# N32H7xx register map
Vendor: Nationstech Ltd.; File version: 1.0
CPU: CM7 r1p1, little endian, MPU, FPU, 4 interrupt priority bits
Registers are 32-bit, read-write, reset 0x0 unless marked. A register's access mark holds for its fields unless they carry their own. Offsets are from the block's base; [hi:lo] are bit positions; {n}, {i} and the like mark numbered series; 'fields as' and 'values as' point back to an identical list.

## ETH1 — Ethernet 1
Base 0x400F4000
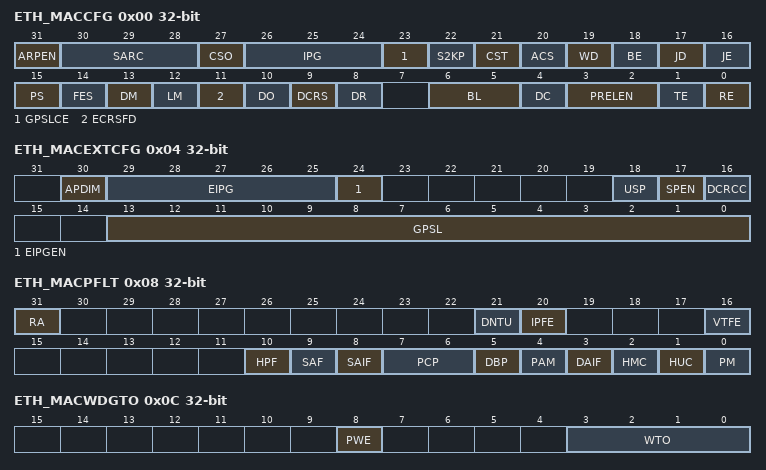
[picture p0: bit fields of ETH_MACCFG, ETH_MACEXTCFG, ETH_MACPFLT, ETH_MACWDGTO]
0x00 ETH_MACCFG
  [31] ARPEN, [30:28] SARC, [27] CSO, [26:24] IPG, [23] GPSLCE, [22] S2KP, [21] CST, [20] ACS, [19] WD, [18] BE, [17] JD, [16] JE, [15] PS, [14] FES, [13] DM, [12] LM, [11] ECRSFD, [10] DO, [9] DCRS, [8] DR, [6:5] BL, [4] DC, [3:2] PRELEN, [1] TE, [0] RE
0x04 ETH_MACEXTCFG
  [30] APDIM, [29:25] EIPG, [24] EIPGEN, [18] USP, [17] SPEN, [16] DCRCC, [13:0] GPSL
0x08 ETH_MACPFLT
  [31] RA, [21] DNTU, [20] IPFE, [16] VTFE, [10] HPF, [9] SAF, [8] SAIF, [7:6] PCP, [5] DBP, [4] PAM, [3] DAIF, [2] HMC, [1] HUC, [0] PM
0x0C ETH_MACWDGTO
  [8] PWE, [3:0] WTO
0x10 ETH_MACHASHTR0
  [31:0] HT31T0
0x14 ETH_MACHASHTR1
  [31:0] HT63T32
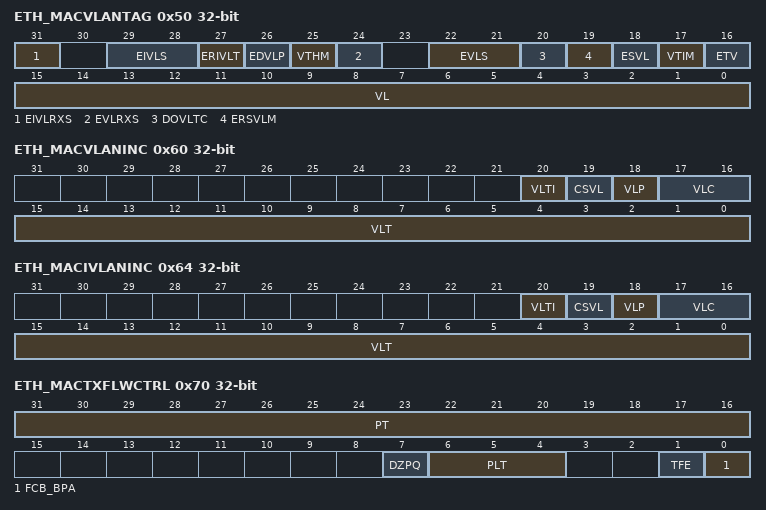
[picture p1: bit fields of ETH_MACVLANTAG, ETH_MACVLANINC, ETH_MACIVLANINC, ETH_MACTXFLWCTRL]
0x50 ETH_MACVLANTAG
  [31] EIVLRXS, [29:28] EIVLS, [27] ERIVLT, [26] EDVLP, [25] VTHM, [24] EVLRXS, [22:21] EVLS, [20] DOVLTC, [19] ERSVLM, [18] ESVL, [17] VTIM, [16] ETV, [15:0] VL
0x58 ETH_MACVHASHT
  [15:0] VLHT
0x60 ETH_MACVLANINC
  [20] VLTI, [19] CSVL, [18] VLP, [17:16] VLC, [15:0] VLT
0x64 ETH_MACIVLANINC
  [20] VLTI, [19] CSVL, [18] VLP, [17:16] VLC, [15:0] VLT
0x70 ETH_MACTXFLWCTRL
  [31:16] PT, [7] DZPQ, [6:4] PLT, [1] TFE, [0] FCB_BPA
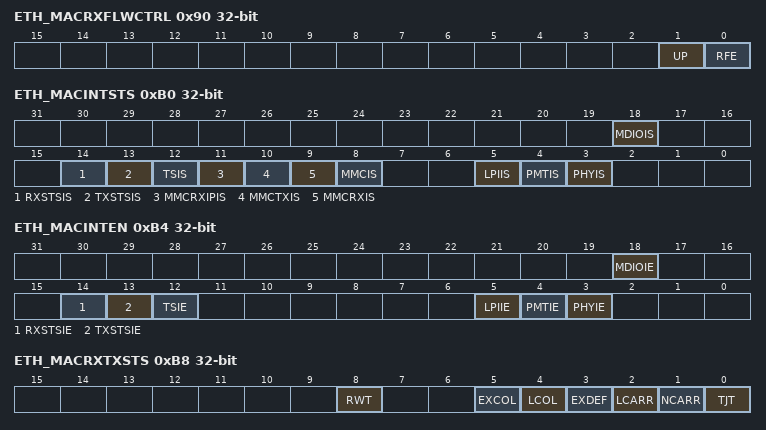
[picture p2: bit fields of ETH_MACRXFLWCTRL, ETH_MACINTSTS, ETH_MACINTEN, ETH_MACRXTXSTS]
0x90 ETH_MACRXFLWCTRL
  [1] UP, [0] RFE
0xB0 ETH_MACINTSTS ro
  [18] MDIOIS, [14] RXSTSIS, [13] TXSTSIS, [12] TSIS, [11] MMCRXIPIS, [10] MMCTXIS, [9] MMCRXIS, [8] MMCIS, [5] LPIIS, [4] PMTIS, [3] PHYIS
0xB4 ETH_MACINTEN
  [18] MDIOIE, [14] RXSTSIE, [13] TXSTSIE, [12] TSIE, [5] LPIIE, [4] PMTIE, [3] PHYIE
0xB8 ETH_MACRXTXSTS ro
  [8] RWT, [5] EXCOL, [4] LCOL, [3] EXDEF, [2] LCARR, [1] NCARR, [0] TJT
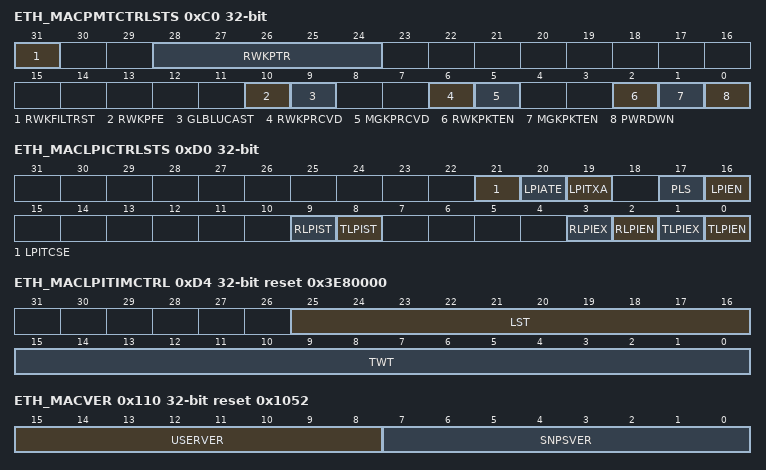
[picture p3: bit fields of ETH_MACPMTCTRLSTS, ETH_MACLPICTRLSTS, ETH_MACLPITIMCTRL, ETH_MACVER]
0xC0 ETH_MACPMTCTRLSTS
  [31] RWKFILTRST, [28:24] RWKPTR ro, [10] RWKPFE, [9] GLBLUCAST, [6] RWKPRCVD ro, [5] MGKPRCVD ro, [2] RWKPKTEN, [1] MGKPKTEN, [0] PWRDWN
0xC4 ETH_MACRWUPFLT
  [31:0] WKUPFRMFTR
0xD0 ETH_MACLPICTRLSTS
  [21] LPITCSE, [20] LPIATE, [19] LPITXA, [17] PLS, [16] LPIEN, [9] RLPIST ro, [8] TLPIST ro, [3] RLPIEX ro, [2] RLPIEN ro, [1] TLPIEX ro, [0] TLPIEN ro
0xD4 ETH_MACLPITIMCTRL reset 0x3E80000
  [25:16] LST, [15:0] TWT
0xD8 ETH_MACLPIETYTIM
  [19:3] LPIET
0xDC ETH_MAC1USTICCNT reset 0x63
  [11:0] TIC1USCNTR
0x110 ETH_MACVER ro reset 0x1052
  [15:8] USERVER, [7:0] SNPSVER
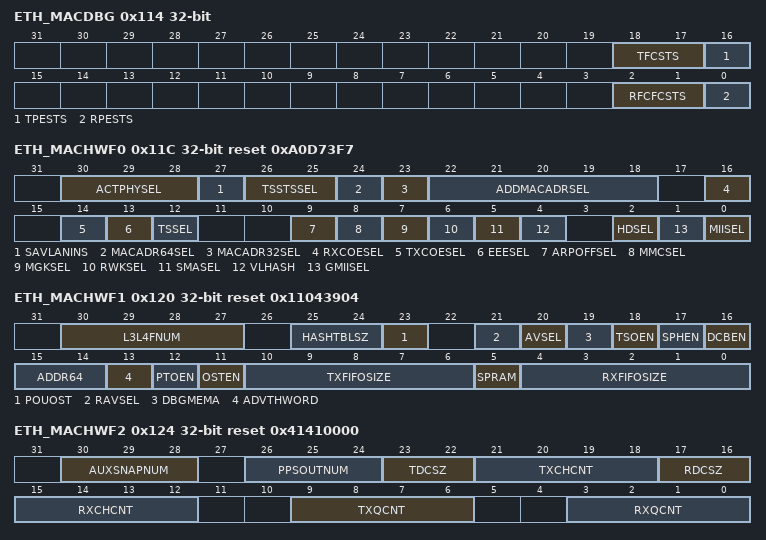
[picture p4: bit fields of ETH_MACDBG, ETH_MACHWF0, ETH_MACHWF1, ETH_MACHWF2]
0x114 ETH_MACDBG ro
  [18:17] TFCSTS, [16] TPESTS, [2:1] RFCFCSTS, [0] RPESTS
0x11C ETH_MACHWF0 ro reset 0xA0D73F7
  [30:28] ACTPHYSEL, [27] SAVLANINS, [26:25] TSSTSSEL, [24] MACADR64SEL, [23] MACADR32SEL, [22:18] ADDMACADRSEL, [16] RXCOESEL, [14] TXCOESEL, [13] EEESEL, [12] TSSEL, [9] ARPOFFSEL, [8] MMCSEL, [7] MGKSEL, [6] RWKSEL, [5] SMASEL, [4] VLHASH, [2] HDSEL, [1] GMIISEL, [0] MIISEL
0x120 ETH_MACHWF1 ro reset 0x11043904
  [30:27] L3L4FNUM, [25:24] HASHTBLSZ, [23] POUOST, [21] RAVSEL, [20] AVSEL, [19] DBGMEMA, [18] TSOEN, [17] SPHEN, [16] DCBEN, [15:14] ADDR64, [13] ADVTHWORD, [12] PTOEN, [11] OSTEN, [10:6] TXFIFOSIZE, [5] SPRAM, [4:0] RXFIFOSIZE
0x124 ETH_MACHWF2 ro reset 0x41410000
  [30:28] AUXSNAPNUM, [26:24] PPSOUTNUM, [23:22] TDCSZ, [21:18] TXCHCNT, [17:16] RDCSZ, [15:12] RXCHCNT, [9:6] TXQCNT, [3:0] RXQCNT
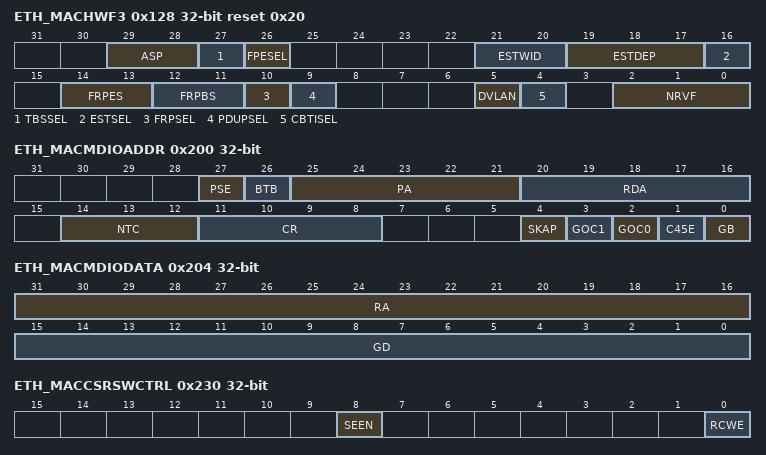
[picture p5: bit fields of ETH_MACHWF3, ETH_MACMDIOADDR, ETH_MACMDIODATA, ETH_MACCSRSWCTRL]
0x128 ETH_MACHWF3 ro reset 0x20
  [29:28] ASP, [27] TBSSEL, [26] FPESEL, [21:20] ESTWID, [19:17] ESTDEP, [16] ESTSEL, [14:13] FRPES, [12:11] FRPBS, [10] FRPSEL, [9] PDUPSEL, [5] DVLAN, [4] CBTISEL, [2:0] NRVF
0x200 ETH_MACMDIOADDR
  [27] PSE, [26] BTB, [25:21] PA, [20:16] RDA, [14:12] NTC, [11:8] CR, [4] SKAP, [3] GOC1, [2] GOC0, [1] C45E, [0] GB
0x204 ETH_MACMDIODATA
  [31:16] RA, [15:0] GD
0x210 ETH_MACARPADDR
  [31:0] ARPPA
0x230 ETH_MACCSRSWCTRL
  [8] SEEN, [0] RCWE
0x240 ETH_MACPTNS
  [31:0] MPTN
0x244 ETH_MACPTUPDT
  [31:0] MPTU
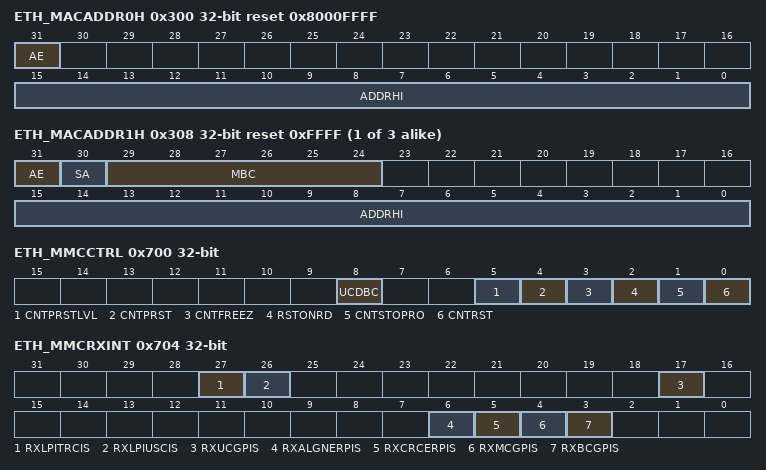
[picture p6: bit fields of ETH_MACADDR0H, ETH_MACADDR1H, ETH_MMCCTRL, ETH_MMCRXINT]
0x300 ETH_MACADDR0H reset 0x8000FFFF
  [31] AE ro, [15:0] ADDRHI
{0x304+8i} ETH_MACADDR{i}L reset 0xFFFFFFFF (i=0..3)
  [31:0] ADDRLO
{0x300+8i} ETH_MACADDR{i}H reset 0xFFFF (i=1..3)
  [31] AE, [30] SA, [29:24] MBC, [15:0] ADDRHI
0x700 ETH_MMCCTRL
  [8] UCDBC, [5] CNTPRSTLVL, [4] CNTPRST, [3] CNTFREEZ, [2] RSTONRD, [1] CNTSTOPRO, [0] CNTRST
0x704 ETH_MMCRXINT ro
  [27] RXLPITRCIS, [26] RXLPIUSCIS, [17] RXUCGPIS, [6] RXALGNERPIS, [5] RXCRCERPIS, [4] RXMCGPIS, [3] RXBCGPIS
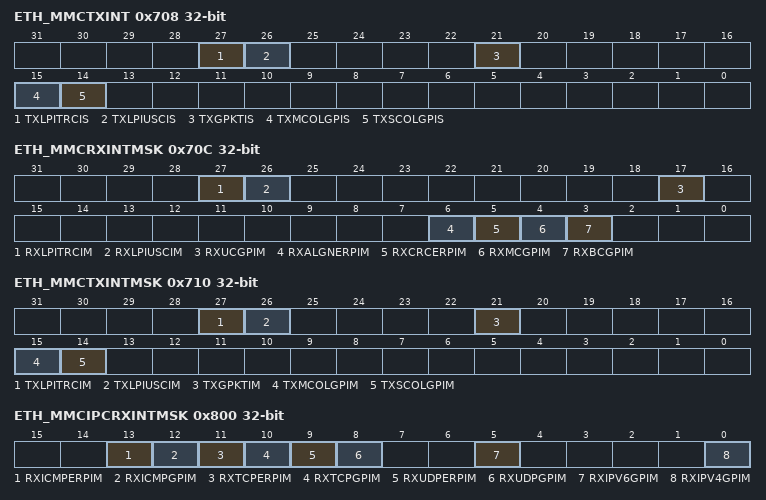
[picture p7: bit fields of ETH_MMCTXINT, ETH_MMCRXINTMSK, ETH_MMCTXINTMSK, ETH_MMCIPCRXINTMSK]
0x708 ETH_MMCTXINT ro
  [27] TXLPITRCIS, [26] TXLPIUSCIS, [21] TXGPKTIS, [15] TXMCOLGPIS, [14] TXSCOLGPIS
0x70C ETH_MMCRXINTMSK
  [27] RXLPITRCIM, [26] RXLPIUSCIM, [17] RXUCGPIM, [6] RXALGNERPIM, [5] RXCRCERPIM, [4] RXMCGPIM, [3] RXBCGPIM
0x710 ETH_MMCTXINTMSK
  [27] TXLPITRCIM, [26] TXLPIUSCIM, [21] TXGPKTIM, [15] TXMCOLGPIM, [14] TXSCOLGPIM
0x74C ETH_MMCTXSCGP ro
  [31:0] TXSNGLCOLG
0x750 ETH_MMCTXMCGP ro
  [31:0] TXMULTCOLG
0x768 ETH_MMCTXPCG ro
  [31:0] TXPKTG
0x78C ETH_MMCRXBPG ro
  [31:0] RXBCASTG
0x790 ETH_MMCRXMPG ro
  [31:0] RXMCASTG
0x794 ETH_MMCRXCRCEP ro
  [31:0] RXCRCERR
0x798 ETH_MMCRXAEP ro
  [31:0] RXALGNERR
0x7C4 ETH_MMCRXUPG ro
  [31:0] RXUCASTG
0x7EC ETH_MMCTXLPIUS ro
  [31:0] TXLPIUSC
0x7F0 ETH_MMCTXLPITRAN ro
  [31:0] TXLPITRC
0x7F4 ETH_MMCRXLPIUS ro
  [31:0] RXLPIUSC
0x7F8 ETH_MMCRXLPITRAN ro
  [31:0] RXLPITRC
0x800 ETH_MMCIPCRXINTMSK
  [13] RXICMPERPIM, [12] RXICMPGPIM, [11] RXTCPERPIM, [10] RXTCPGPIM, [9] RXUDPERPIM, [8] RXUDPGPIM, [5] RXIPV6GPIM, [0] RXIPV4GPIM
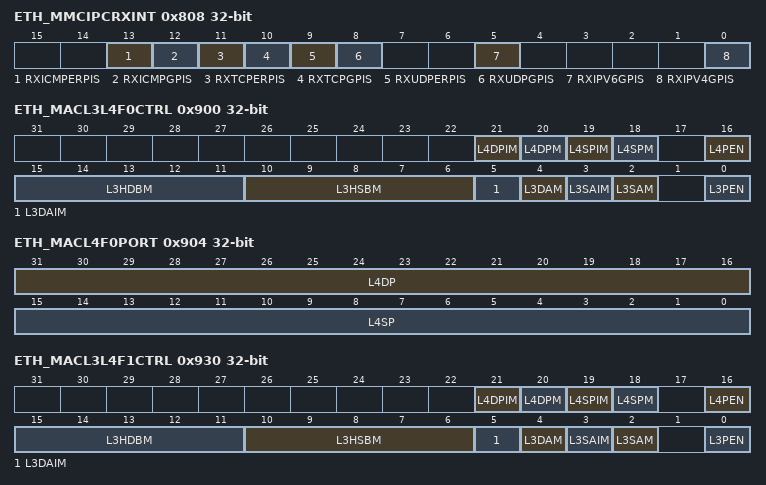
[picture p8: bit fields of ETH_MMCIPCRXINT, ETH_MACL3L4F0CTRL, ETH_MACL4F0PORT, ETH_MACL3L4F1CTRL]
0x808 ETH_MMCIPCRXINT ro
  [13] RXICMPERPIS, [12] RXICMPGPIS, [11] RXTCPERPIS, [10] RXTCPGPIS, [9] RXUDPERPIS, [8] RXUDPGPIS, [5] RXIPV6GPIS, [0] RXIPV4GPIS
0x810 ETH_MMCRXIPV4GP ro
  [31:0] RXIPV4GDPKT
0x824 ETH_MMCRXIPV6GP ro
  [31:0] RXIPV6GDPKT
0x830 ETH_MMCRXUDPGP ro
  [31:0] RXUDPGDPKT
0x834 ETH_MMCRXUDPEP ro
  [31:0] RXUDPERRPKT
0x838 ETH_MMCRXTCPGP ro
  [31:0] RXTCPGDPKT
0x83C ETH_MMCRXTCPEP ro
  [31:0] RXTCPERRPKT
0x840 ETH_MMCRXICMPGP ro
  [31:0] RXICMPGDPKT
0x844 ETH_MMCRXICMPEP ro
  [31:0] RXICMPERRPKT
0x900 ETH_MACL3L4F0CTRL
  [21] L4DPIM, [20] L4DPM, [19] L4SPIM, [18] L4SPM, [16] L4PEN, [15:11] L3HDBM, [10:6] L3HSBM, [5] L3DAIM, [4] L3DAM, [3] L3SAIM, [2] L3SAM, [0] L3PEN
0x904 ETH_MACL4F0PORT
  [31:16] L4DP, [15:0] L4SP
{0x910+4i} ETH_MACL3F0ADDR{i} (i=0..3)
  [31:0] L3A{i}
0x930 ETH_MACL3L4F1CTRL
  fields as ETH_MACL3L4F0CTRL
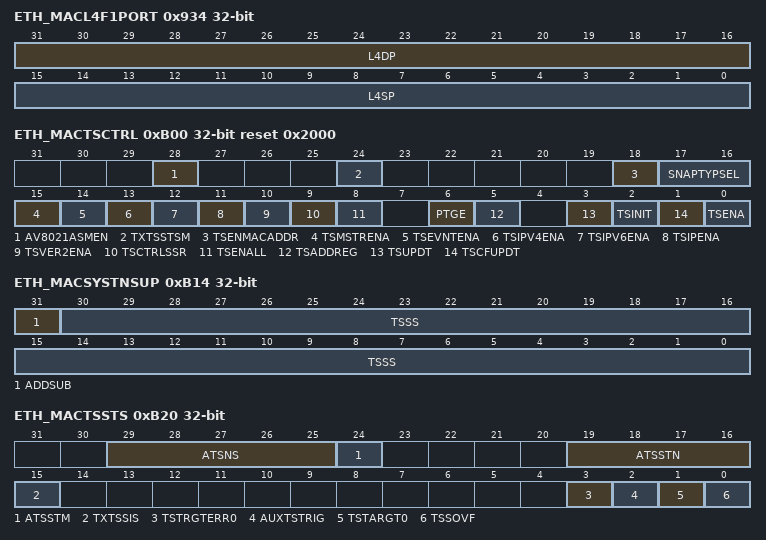
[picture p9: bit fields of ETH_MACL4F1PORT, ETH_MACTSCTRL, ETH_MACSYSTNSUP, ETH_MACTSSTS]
0x934 ETH_MACL4F1PORT
  [31:16] L4DP, [15:0] L4SP
{0x940+4i} ETH_MACL3F1ADDR{i} (i=0..3)
  [31:0] L3A{i}
0xB00 ETH_MACTSCTRL reset 0x2000
  [28] AV8021ASMEN, [24] TXTSSTSM, [18] TSENMACADDR, [17:16] SNAPTYPSEL, [15] TSMSTRENA, [14] TSEVNTENA, [13] TSIPV4ENA, [12] TSIPV6ENA, [11] TSIPENA, [10] TSVER2ENA, [9] TSCTRLSSR, [8] TSENALL, [6] PTGE, [5] TSADDREG, [3] TSUPDT, [2] TSINIT, [1] TSCFUPDT, [0] TSENA
0xB04 ETH_MACSUBSINC
  [23:16] SSINC
0xB08 ETH_MACSYSTS ro
  [31:0] TSS
0xB0C ETH_MACSYSTNS ro
  [31:0] TSS
0xB10 ETH_MACSYSTSUP
  [31:0] TSS
0xB14 ETH_MACSYSTNSUP
  [31] ADDSUB, [30:0] TSSS
0xB18 ETH_MACTSADD
  [31:0] TSAR
0xB1C ETH_MACSYSTHWS
  [15:0] TSHWR
0xB20 ETH_MACTSSTS ro
  [29:25] ATSNS, [24] ATSSTM, [19:16] ATSSTN, [15] TXTSSIS, [3] TSTRGTERR0, [2] AUXTSTRIG, [1] TSTARGT0, [0] TSSOVF
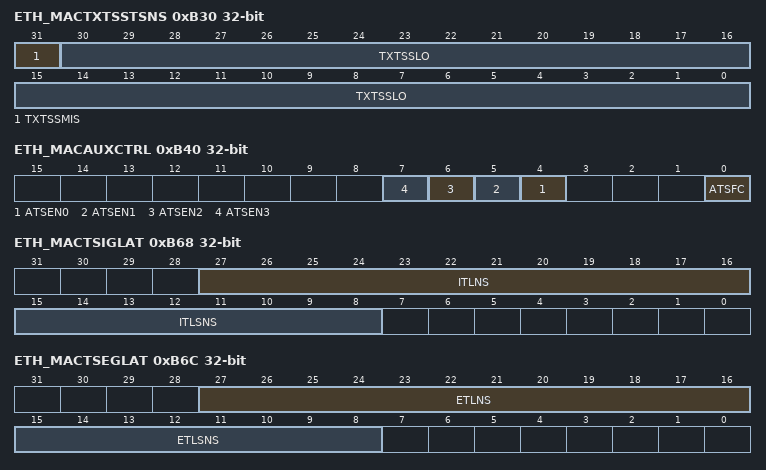
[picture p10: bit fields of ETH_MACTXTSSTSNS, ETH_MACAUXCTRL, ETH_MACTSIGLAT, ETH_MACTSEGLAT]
0xB30 ETH_MACTXTSSTSNS
  [31] TXTSSMIS, [30:0] TXTSSLO ro
0xB34 ETH_MACTXTSSTSS ro
  [31:0] TXTSSHI
0xB40 ETH_MACAUXCTRL
  [n+4] ATSEN{n} (n=0..3), [0] ATSFC
0xB48 ETH_MACAUXTSNS ro
  [30:0] AUXTSLO
0xB4C ETH_MACAUXTSS ro
  [31:0] AUXTSHI
0xB50 ETH_MACTSIGASYC
  [31:0] OSTIAC
0xB54 ETH_MACTSEGASYC
  [31:0] OSTEAC
0xB58 ETH_MACTSIGCNS
  [31:0] TSIC
0xB5C ETH_MACTSEGCNS
  [31:0] TSEC
0xB68 ETH_MACTSIGLAT ro
  [27:16] ITLNS, [15:8] ITLSNS
0xB6C ETH_MACTSEGLAT ro
  [27:16] ETLNS, [15:8] ETLSNS
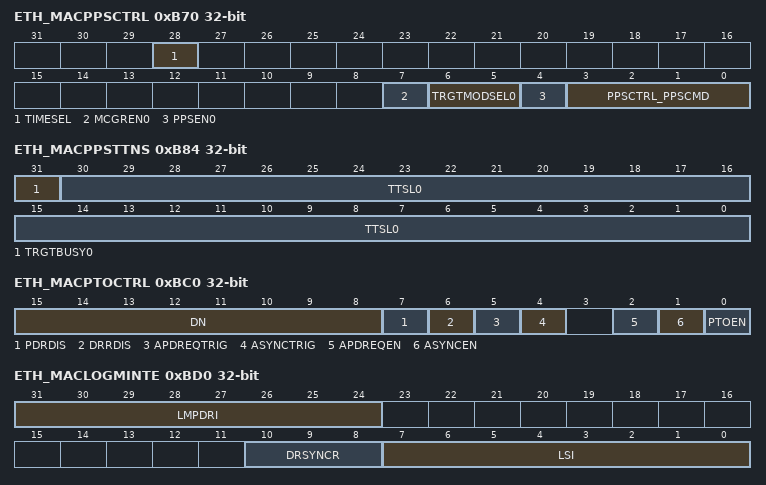
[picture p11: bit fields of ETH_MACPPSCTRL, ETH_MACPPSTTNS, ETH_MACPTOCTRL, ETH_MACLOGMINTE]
0xB70 ETH_MACPPSCTRL
  [28] TIMESEL, [7] MCGREN0, [6:5] TRGTMODSEL0, [4] PPSEN0, [3:0] PPSCTRL_PPSCMD
0xB80 ETH_MACPPSTTS
  [31:0] TSTRH0
0xB84 ETH_MACPPSTTNS
  [31] TRGTBUSY0, [30:0] TTSL0
0xB88 ETH_MACPPSINTE
  [31:0] PPSINT0
0xB8C ETH_MACPPSWID
  [31:0] PPSWIDTH0
0xBC0 ETH_MACPTOCTRL
  [15:8] DN, [7] PDRDIS, [6] DRRDIS, [5] APDREQTRIG, [4] ASYNCTRIG, [2] APDREQEN, [1] ASYNCEN, [0] PTOEN
0xBC4 ETH_MACSRCPID0
  [31:0] SPI0
0xBC8 ETH_MACSRCPID1
  [31:0] SPI1
0xBCC ETH_MACSRCPID2
  [15:0] SPI2
0xBD0 ETH_MACLOGMINTE
  [31:24] LMPDRI, [10:8] DRSYNCR, [7:0] LSI
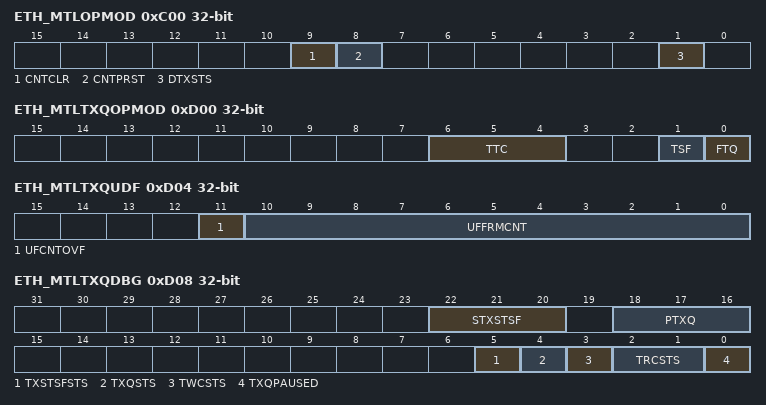
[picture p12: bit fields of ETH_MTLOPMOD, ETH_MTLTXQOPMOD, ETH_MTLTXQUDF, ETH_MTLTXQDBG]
0xC00 ETH_MTLOPMOD
  [9] CNTCLR, [8] CNTPRST, [1] DTXSTS
0xC20 ETH_MTLINTSTS
  [0] Q0IS
0xD00 ETH_MTLTXQOPMOD
  [6:4] TTC, [1] TSF, [0] FTQ
0xD04 ETH_MTLTXQUDF ro
  [11] UFCNTOVF, [10:0] UFFRMCNT
0xD08 ETH_MTLTXQDBG ro
  [22:20] STXSTSF, [18:16] PTXQ, [5] TXSTSFSTS, [4] TXQSTS, [3] TWCSTS, [2:1] TRCSTS, [0] TXQPAUSED
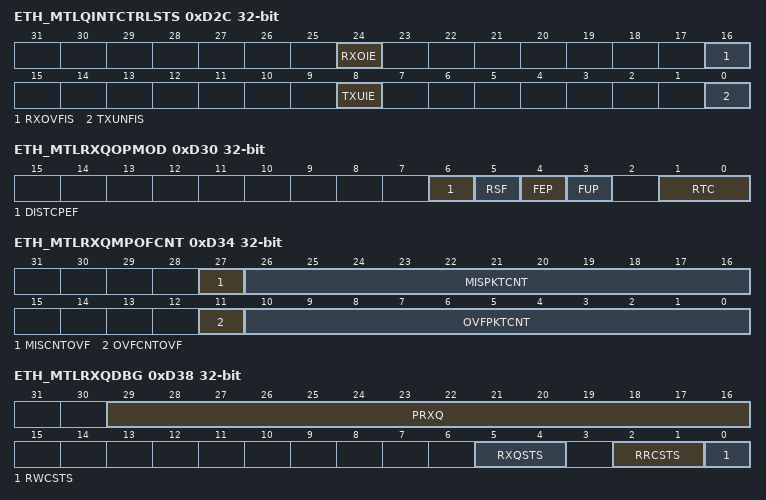
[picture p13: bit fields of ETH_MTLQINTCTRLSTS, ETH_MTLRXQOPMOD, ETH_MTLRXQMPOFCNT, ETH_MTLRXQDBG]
0xD2C ETH_MTLQINTCTRLSTS
  [24] RXOIE, [16] RXOVFIS, [8] TXUIE, [0] TXUNFIS
0xD30 ETH_MTLRXQOPMOD
  [6] DISTCPEF, [5] RSF, [4] FEP, [3] FUP, [1:0] RTC
0xD34 ETH_MTLRXQMPOFCNT ro
  [27] MISCNTOVF, [26:16] MISPKTCNT, [11] OVFCNTOVF, [10:0] OVFPKTCNT
0xD38 ETH_MTLRXQDBG ro
  [29:16] PRXQ, [5:4] RXQSTS, [2:1] RRCSTS, [0] RWCSTS
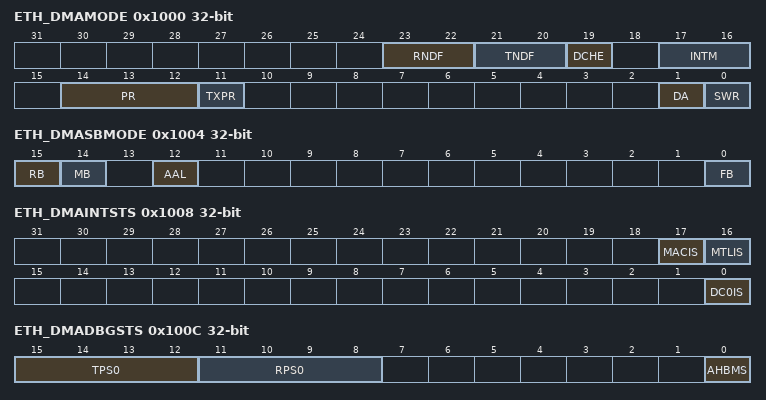
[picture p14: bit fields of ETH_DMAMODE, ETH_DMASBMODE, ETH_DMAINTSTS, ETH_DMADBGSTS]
0x1000 ETH_DMAMODE
  [23:22] RNDF, [21:20] TNDF, [19] DCHE, [17:16] INTM, [14:12] PR, [11] TXPR, [1] DA, [0] SWR
0x1004 ETH_DMASBMODE
  [15] RB, [14] MB, [12] AAL, [0] FB
0x1008 ETH_DMAINTSTS ro
  [17] MACIS, [16] MTLIS, [0] DC0IS
0x100C ETH_DMADBGSTS ro
  [15:12] TPS0, [11:8] RPS0, [0] AHBMS
0x1100 ETH_DMACH0CTRL
  [20:18] DSL, [16] PBLx8, [13:0] MSS
0x1104 ETH_DMACH0TXCTRL
  [22] ETIC, [21:16] TxPBL, [12] TSE, [4] OSF, [0] ST
0x1108 ETH_DMACH0RXCTRL
  [31] RPF, [22] ERIC, [21:16] RxPBL, [14:3] RBSZH, [2:1] RBSZL ro, [0] SR
0x1114 ETH_DMACH0TXDLA
  [31:0] TDESLA
0x111C ETH_DMACH0RXDLA
  [31:0] RDESLA
0x1120 ETH_DMACH0TXDTP
  [31:0] TDTP
0x1128 ETH_DMACH0RXDTP
  [31:0] RDTP
0x112C ETH_DMACH0TXDRLEN
  [9:0] TDRL
0x1130 ETH_DMACH0RXCTRL2
  [23:16] ARBS, [9:0] RDRL
0x1134 ETH_DMACH0INTEN
  [15] NIE, [14] AIE, [13] CDEE, [12] FBEE, [11] ERIE, [10] ETIE, [9] RWTE, [8] RSE, [7] RBUE, [6] RIE, [2] TBUE, [1] TXSE, [0] TIE
0x1138 ETH_DMACH0RXINTWT
  [17:16] RWTU, [7:0] RWT
0x1144 ETH_DMACH0CATXD ro
  [31:0] CURTDESAPTR
0x114C ETH_DMACH0CARXD ro
  [31:0] CURRDESAPTR
0x1154 ETH_DMACH0CATXB ro
  [31:0] CURTBUFAPTR
0x115C ETH_DMACH0CARXB ro
  [31:0] CURRBUFAPTR
0x1160 ETH_DMACH0STS
  [21:19] REB ro, [18:16] TEB ro, [15] NIS, [14] AIS, [13] CDE, [12] FBE, [11] ERI, [10] ETI, [9] RWT, [8] RPS, [7] RBU, [6] RI, [2] TBU, [1] TPS, [0] TI
0x1164 ETH_DMACH0DPCNT ro
  [15] DPCO, [10:0] DPC
0x116C ETH_DMACH0RXERICNT ro
  [11:0] ECNT

## ETH2 — Ethernet 2
Base 0x40042000
Registers as ETH1; these are added or differ:
0x00 ETH_MACCFG reset 0x8000
  [31] ARPEN, [30:28] SARC, [27] CSO, [26:24] IPG, [23] GPSLCE, [22] S2KP, [21] CST, [20] ACS, [19] WD, [17] JD, [16] JE, [15] PS ro, [14] FES, [13] DM, [12] LM, [11] ECRSFD, [10] DO, [9] DCRS, [8] DR, [6:5] BL, [4] DC, [3:2] PRELEN, [1] TE, [0] RE
